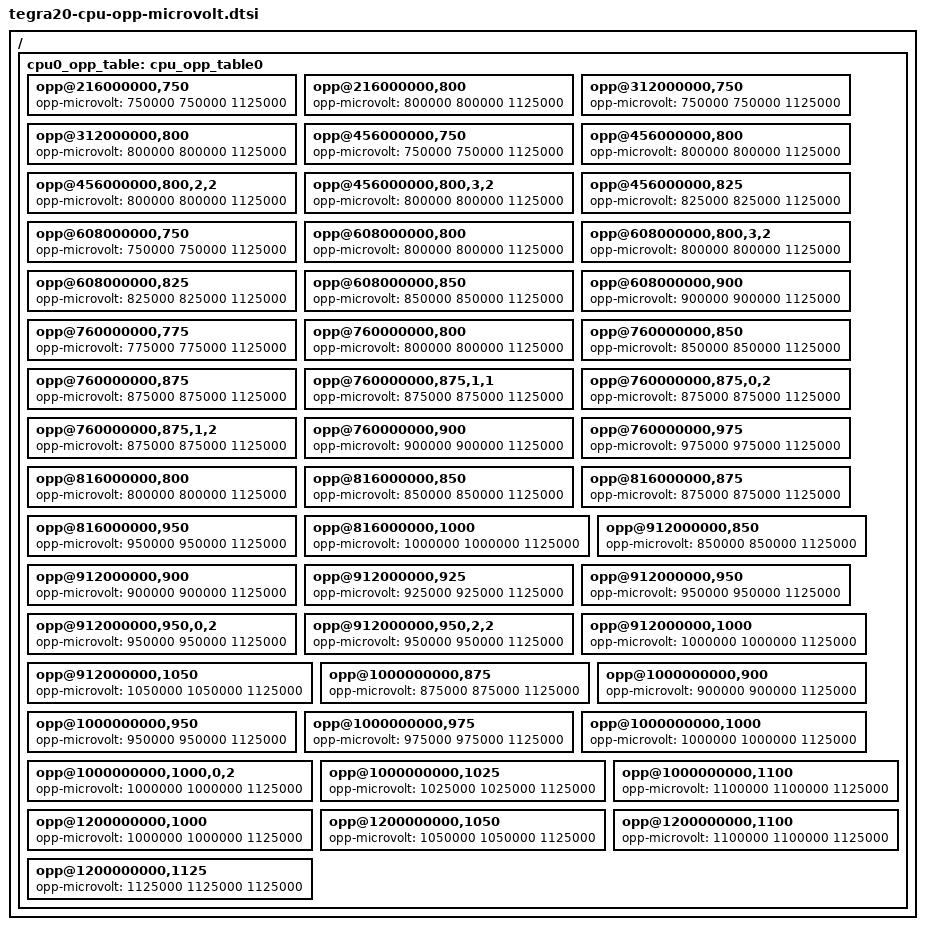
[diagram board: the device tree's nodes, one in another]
// SPDX-License-Identifier: GPL-2.0

/ {
	cpu0_opp_table: cpu_opp_table0 {
		opp@216000000,750 {
			opp-microvolt = <750000 750000 1125000>;
		};

		opp@216000000,800 {
			opp-microvolt = <800000 800000 1125000>;
		};

		opp@312000000,750 {
			opp-microvolt = <750000 750000 1125000>;
		};

		opp@312000000,800 {
			opp-microvolt = <800000 800000 1125000>;
		};

		opp@456000000,750 {
			opp-microvolt = <750000 750000 1125000>;
		};

		opp@456000000,800 {
			opp-microvolt = <800000 800000 1125000>;
		};

		opp@456000000,800,2,2 {
			opp-microvolt = <800000 800000 1125000>;
		};

		opp@456000000,800,3,2 {
			opp-microvolt = <800000 800000 1125000>;
		};

		opp@456000000,825 {
			opp-microvolt = <825000 825000 1125000>;
		};

		opp@608000000,750 {
			opp-microvolt = <750000 750000 1125000>;
		};

		opp@608000000,800 {
			opp-microvolt = <800000 800000 1125000>;
		};

		opp@608000000,800,3,2 {
			opp-microvolt = <800000 800000 1125000>;
		};

		opp@608000000,825 {
			opp-microvolt = <825000 825000 1125000>;
		};

		opp@608000000,850 {
			opp-microvolt = <850000 850000 1125000>;
		};

		opp@608000000,900 {
			opp-microvolt = <900000 900000 1125000>;
		};

		opp@760000000,775 {
			opp-microvolt = <775000 775000 1125000>;
		};

		opp@760000000,800 {
			opp-microvolt = <800000 800000 1125000>;
		};

		opp@760000000,850 {
			opp-microvolt = <850000 850000 1125000>;
		};

		opp@760000000,875 {
			opp-microvolt = <875000 875000 1125000>;
		};

		opp@760000000,875,1,1 {
			opp-microvolt = <875000 875000 1125000>;
		};

		opp@760000000,875,0,2 {
			opp-microvolt = <875000 875000 1125000>;
		};

		opp@760000000,875,1,2 {
			opp-microvolt = <875000 875000 1125000>;
		};

		opp@760000000,900 {
			opp-microvolt = <900000 900000 1125000>;
		};

		opp@760000000,975 {
			opp-microvolt = <975000 975000 1125000>;
		};

		opp@816000000,800 {
			opp-microvolt = <800000 800000 1125000>;
		};

		opp@816000000,850 {
			opp-microvolt = <850000 850000 1125000>;
		};

		opp@816000000,875 {
			opp-microvolt = <875000 875000 1125000>;
		};

		opp@816000000,950 {
			opp-microvolt = <950000 950000 1125000>;
		};

		opp@816000000,1000 {
			opp-microvolt = <1000000 1000000 1125000>;
		};

		opp@912000000,850 {
			opp-microvolt = <850000 850000 1125000>;
		};

		opp@912000000,900 {
			opp-microvolt = <900000 900000 1125000>;
		};

		opp@912000000,925 {
			opp-microvolt = <925000 925000 1125000>;
		};

		opp@912000000,950 {
			opp-microvolt = <950000 950000 1125000>;
		};

		opp@912000000,950,0,2 {
			opp-microvolt = <950000 950000 1125000>;
		};

		opp@912000000,950,2,2 {
			opp-microvolt = <950000 950000 1125000>;
		};

		opp@912000000,1000 {
			opp-microvolt = <1000000 1000000 1125000>;
		};

		opp@912000000,1050 {
			opp-microvolt = <1050000 1050000 1125000>;
		};

		opp@1000000000,875 {
			opp-microvolt = <875000 875000 1125000>;
		};

		opp@1000000000,900 {
			opp-microvolt = <900000 900000 1125000>;
		};

		opp@1000000000,950 {
			opp-microvolt = <950000 950000 1125000>;
		};

		opp@1000000000,975 {
			opp-microvolt = <975000 975000 1125000>;
		};

		opp@1000000000,1000 {
			opp-microvolt = <1000000 1000000 1125000>;
		};

		opp@1000000000,1000,0,2 {
			opp-microvolt = <1000000 1000000 1125000>;
		};

		opp@1000000000,1025 {
			opp-microvolt = <1025000 1025000 1125000>;
		};

		opp@1000000000,1100 {
			opp-microvolt = <1100000 1100000 1125000>;
		};

		opp@1200000000,1000 {
			opp-microvolt = <1000000 1000000 1125000>;
		};

		opp@1200000000,1050 {
			opp-microvolt = <1050000 1050000 1125000>;
		};

		opp@1200000000,1100 {
			opp-microvolt = <1100000 1100000 1125000>;
		};

		opp@1200000000,1125 {
			opp-microvolt = <1125000 1125000 1125000>;
		};
	};
};
